# lilium_network register map
Vendor: Nordic Semiconductor; Series: nrfXX; File version: 1
nRFXX reference description for system-on-chip with dual ARM 32-bit Cortex-M33 microcontrollers
CPU: CM33 r0p4, little endian, MPU, no FPU, 3 interrupt priority bits, 30 interrupts
Registers are 32-bit, read-write, reset 0x0 unless marked. A register's access mark holds for its fields unless they carry their own. Offsets are from the block's base; lines under a group give offsets from that group; [hi:lo] are bit positions; {n}, {i} and the like mark numbered series; 'fields as' and 'values as' point back to an identical list; <NAME> marks a mode.

## Memory map
0x41008000 RADIO size 0x2000 — 2.4 GHz radio
0x4100D000 ECB size 0x1000 — AES ECB Mode Encryption
0x4100E000 AAR size 0x1000 — Accelerated Address Resolver
0x4100E000 CCM size 0x1000 — AES CCM Mode Encryption
0x41010000 TEMP size 0x1000 — Temperature Sensor
0x41015000 ANACONF size 0x1000 — Analog Trim and Configuration Registers
0x4101A000 COMP size 0x1000 — Comparator
0x4101C000 SAADC size 0x1000 — Analog to Digital Converter
0x418C0500 GPIOINTERNAL size 0x1000 — GPIO Static
0x418C0500 P0 size 0x300 — GPIO Port

## Interrupts
8 RADIO0 (RADIO)
9 RADIO1 (RADIO)
13 ECB
14 AAR_CCM (AAR, CCM)
16 TEMP
26 COMP
28 SAADC

## Further device data
MaxInterrupts=129

## ECB — AES ECB Mode Encryption
Base 0x4100D000
0x00 TASKS_START wo — Start ECB block encrypt
  [0] TASKS_START
    1=Trigger task
0x04 TASKS_STOP wo — Abort a possible executing ECB operation
  [0] TASKS_STOP
    1=Trigger task
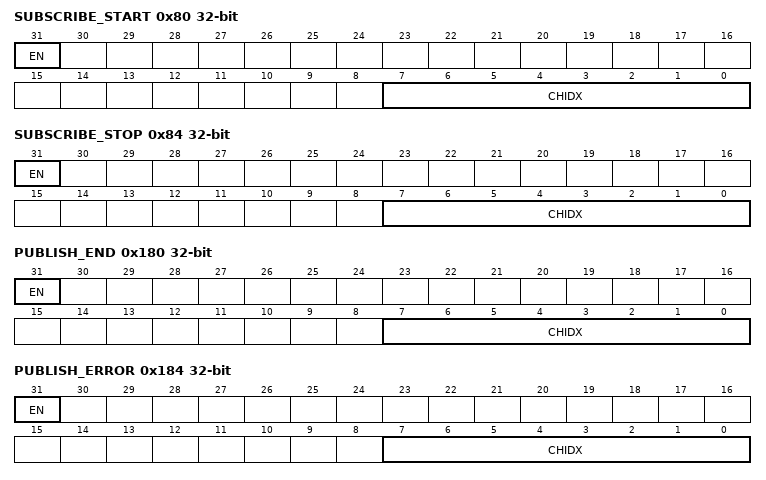
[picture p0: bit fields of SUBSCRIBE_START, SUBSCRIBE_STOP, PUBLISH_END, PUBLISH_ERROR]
0x80 SUBSCRIBE_START — Subscribe configuration for task START
  [31] EN
    0=Disabled (Disable subscription); 1=Enabled (Enable subscription)
  [7:0] CHIDX — DPPI channel that task START will subscribe to
0x84 SUBSCRIBE_STOP — Subscribe configuration for task STOP
  [31] EN
    values as SUBSCRIBE_START.EN
  [7:0] CHIDX — DPPI channel that task STOP will subscribe to
0x100 EVENTS_END — ECB block encrypt complete
  [0] EVENTS_END
    0=NotGenerated (Event not generated); 1=Generated (Event generated)
0x104 EVENTS_ERROR — ECB block encrypt aborted because of a STOP task or due to an error
  [0] EVENTS_ERROR
    values as EVENTS_END.EVENTS_END
0x180 PUBLISH_END — Publish configuration for event END
  [31] EN
    0=Disabled (Disable publishing); 1=Enabled (Enable publishing)
  [7:0] CHIDX — DPPI channel that event END will publish to
0x184 PUBLISH_ERROR — Publish configuration for event ERROR
  [31] EN
    values as PUBLISH_END.EN
  [7:0] CHIDX — DPPI channel that event ERROR will publish to
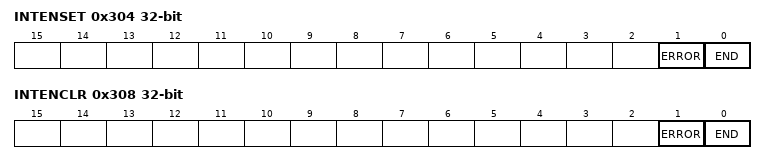
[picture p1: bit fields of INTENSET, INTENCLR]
0x304 INTENSET — Enable interrupt
  [1] ERROR — Write '1' to enable interrupt for event ERROR
    on read: 0=Disabled (Read: Disabled); 1=Enabled (Read: Enabled) | on write: 1=Set (Enable)
  [0] END — Write '1' to enable interrupt for event END
    values as ERROR
0x308 INTENCLR — Disable interrupt
  [1] ERROR — Write '1' to disable interrupt for event ERROR
    on read: 0=Disabled (Read: Disabled); 1=Enabled (Read: Enabled) | on write: 1=Clear (Disable)
  [0] END — Write '1' to disable interrupt for event END
    values as ERROR
0x510 KEY group — Unspecified
  {0x0+4j} VALUE[{j}] (j=0..3) wo — Description collection: 128-bit AES key
    [31:0] VALUE — AES 128-bit key value, bits (32*(i+1))-1 : (32*i)
0x530 IN group — IN EasyDMA channel
  0x00 PTR — Input pointer
    [31:0] PTR — Points to a job list containing unencrypted ECB data structure
  0x04 AMOUNT ro — Number of bytes read from the input data, not including the job list structure
    [31:0] AMOUNT — Number of bytes read from the input data
0x538 OUT group — OUT EasyDMA channel
  0x00 PTR — Output pointer Points to a job list containing encrypted ECB data structure
    [31:0] PTR — Output pointer
  0x04 AMOUNT ro — Number of bytes available in the output data, not including the job list structure
    [31:0] AMOUNT — Number of bytes available in the output data

## Licence text in the file
Copyright (c) 2010 - 2021, Nordic Semiconductor ASA All rights reserved. Redistribution and use in source and binary forms, with or without modification, are permitted provided that the following conditions are met: 1. Redistributions of source code must retain the above copyright notice, this list of conditions and the following disclaimer. 2. Redistributions in binary form, except as embedded into a Nordic Semiconductor ASA integrated circuit in a product or a software update for such product, must reproduce the above copyright notice, this list of conditions and the following disclaimer in the documentation and/or other materials provided with the distribution. 3. Neither the name of Nordic Semiconductor ASA nor the names of its contributors may be used to endorse or promote products derived from this software without specific prior written permission. 4. This software, with or without modification, must only be used with a Nordic Semiconductor ASA integrated circuit. 5. Any software provided in binary form under this license must not be reverse engineered, decompiled, modified and/or disassembled. THIS SOFTWARE IS PROVIDED BY NORDIC SEMICONDUCTOR ASA "AS IS" AND ANY EXPRESS OR IMPLIED WARRANTIES, INCLUDING, BUT NOT LIMITED TO, THE IMPLIED WARRANTIES OF MERCHANTABILITY, NONINFRINGEMENT, AND FITNESS FOR A PARTICULAR PURPOSE ARE DISCLAIMED. IN NO EVENT SHALL NORDIC SEMICONDUCTOR ASA OR CONTRIBUTORS BE LIABLE FOR ANY DIRECT, INDIRECT, INCIDENTAL, SPECIAL, EXEMPLARY, OR CONSEQUENTIAL DAMAGES (INCLUDING, BUT NOT LIMITED TO, PROCUREMENT OF SUBSTITUTE GOODS OR SERVICES; LOSS OF USE, DATA, OR PROFITS; OR BUSINESS INTERRUPTION) HOWEVER CAUSED AND ON ANY THEORY OF LIABILITY, WHETHER IN CONTRACT, STRICT LIABILITY, OR TORT (INCLUDING NEGLIGENCE OR OTHERWISE) ARISING IN ANY WAY OUT OF THE USE OF THIS SOFTWARE, EVEN IF ADVISED OF THE POSSIBILITY OF SUCH DAMAGE.
